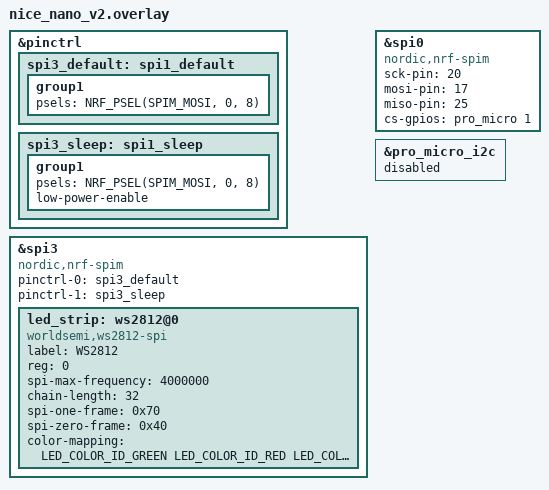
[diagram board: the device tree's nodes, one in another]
#include <dt-bindings/led/led.h>

&pinctrl {
	spi3_default: spi1_default {
		group1 {
			psels = <NRF_PSEL(SPIM_MOSI, 0, 8)>;
		};
	};

	spi3_sleep: spi1_sleep {
		group1 {
			psels = <NRF_PSEL(SPIM_MOSI, 0, 8)>;
			low-power-enable;
		};
	};
};

&spi3 {
	compatible = "nordic,nrf-spim";
	status = "okay";

	pinctrl-0 = <&spi3_default>;
	pinctrl-1 = <&spi3_sleep>;
	pinctrl-names = "default", "sleep";

	led_strip: ws2812@0 {
		compatible = "worldsemi,ws2812-spi";
		label = "WS2812";

		/* SPI */
		reg = <0>; /* ignored, but necessary for SPI bindings */
		spi-max-frequency = <4000000>;

		/* WS2812 */
		chain-length = <32>; /* arbitrary; change at will */
		spi-one-frame = <0x70>;
		spi-zero-frame = <0x40>;

		color-mapping = <LED_COLOR_ID_GREEN LED_COLOR_ID_RED LED_COLOR_ID_BLUE>;
	};
};
nice_view_spi: &spi0 {
	compatible = "nordic,nrf-spim";
	sck-pin = <20>;
	mosi-pin = <17>;
	miso-pin = <25>;
	cs-gpios = <&pro_micro 1 GPIO_ACTIVE_HIGH>;
};

&pro_micro_i2c {
	status = "disabled";
};


